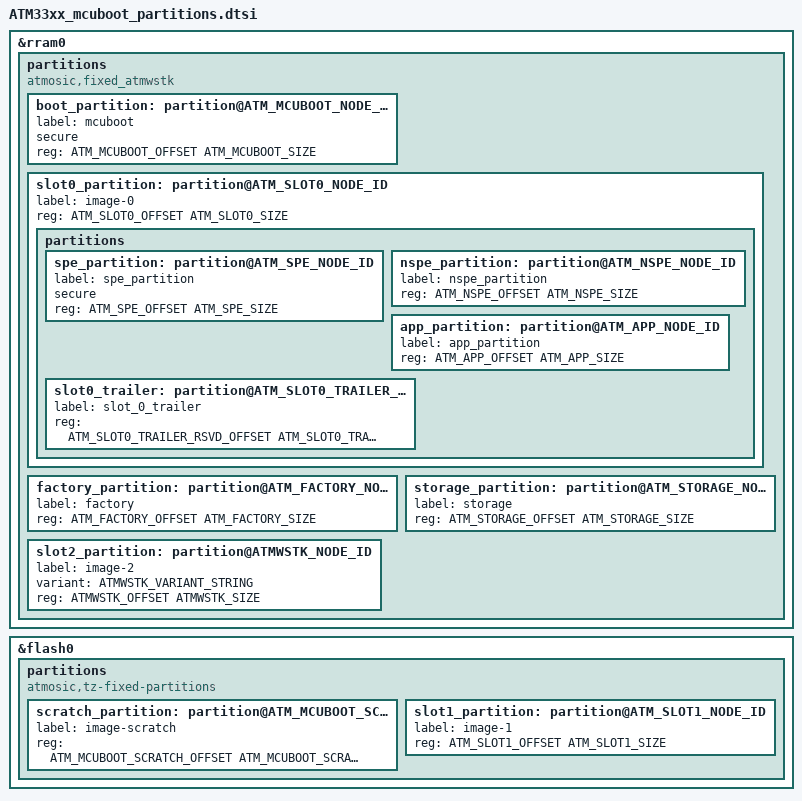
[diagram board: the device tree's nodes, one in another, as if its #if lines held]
/*
 * Copyright (c) 2022-2025 Atmosic
 *
 * SPDX-License-Identifier: Apache-2.0
 */

#if ATM_SPE_SIZE
/delete-node/ &spe_partition;
/delete-node/ &nspe_partition;
#endif
#if ATM_APP_SIZE
/delete-node/ &app_partition;
#endif
/delete-node/ &storage_partition;

#include <arm/atmosic/ATM33xx_mcuboot_partition_defs.h>

&rram0 {
	partitions {
#if ATM_SPE_SIZE
		compatible = "atmosic,fixed_atmwstk", "atmosic,tz-fixed-partitions", "fixed-partitions";
#else
		compatible = "atmosic,fixed_atmwstk", "fixed-partitions";
#endif
		#address-cells = <1>;
		#size-cells = <1>;

		boot_partition: partition@ATM_MCUBOOT_NODE_ID {
			label = "mcuboot";
#if ATM_SPE_SIZE
			secure;
#endif
			reg = <ATM_MCUBOOT_OFFSET ATM_MCUBOOT_SIZE>;
		};
		slot0_partition: partition@ATM_SLOT0_NODE_ID {
			label = "image-0";
			reg = <ATM_SLOT0_OFFSET ATM_SLOT0_SIZE>;
			partitions {
				#address-cells = <1>;
				#size-cells = <1>;
#if ATM_SPE_SIZE
				spe_partition: partition@ATM_SPE_NODE_ID {
					label = "spe_partition";
					secure;
					reg = <ATM_SPE_OFFSET ATM_SPE_SIZE>;
				};
				nspe_partition: partition@ATM_NSPE_NODE_ID {
					label = "nspe_partition";
					reg = <ATM_NSPE_OFFSET ATM_NSPE_SIZE>;
				};
#endif
#if ATM_APP_SIZE
				app_partition: partition@ATM_APP_NODE_ID {
					label = "app_partition";
					reg = <ATM_APP_OFFSET ATM_APP_SIZE>;
				};
#endif
#if ATM_SLOT0_TRAILER_RSVD_SIZE
				slot0_trailer: partition@ATM_SLOT0_TRAILER_NODE_ID {
					label = "slot_0_trailer";
					reg = <ATM_SLOT0_TRAILER_RSVD_OFFSET ATM_SLOT0_TRAILER_RSVD_SIZE>;
				};
#endif
			};
		};
		factory_partition: partition@ATM_FACTORY_NODE_ID {
			label = "factory";
			reg = <ATM_FACTORY_OFFSET ATM_FACTORY_SIZE>;
		};
		storage_partition: partition@ATM_STORAGE_NODE_ID {
			label = "storage";
			reg = <ATM_STORAGE_OFFSET ATM_STORAGE_SIZE>;
		};
#if ATMWSTK_SIZE
		slot2_partition: partition@ATMWSTK_NODE_ID {
			label = "image-2";
			variant = ATMWSTK_VARIANT_STRING;
			reg = <ATMWSTK_OFFSET ATMWSTK_SIZE>;
		};
#endif
	};
};

&flash0 {
	partitions {
		compatible = "atmosic,tz-fixed-partitions", "fixed-partitions";
		#address-cells = <1>;
		#size-cells = <1>;
#if ATM_MCUBOOT_SCRATCH_SIZE
		scratch_partition: partition@ATM_MCUBOOT_SCRATCH_NODE_ID {
			label = "image-scratch";
			reg = <ATM_MCUBOOT_SCRATCH_OFFSET ATM_MCUBOOT_SCRATCH_SIZE>;
		};
#endif
		// slot1 OTA staging area in flash, size must equal slot0_partition
		slot1_partition: partition@ATM_SLOT1_NODE_ID {
			label = "image-1";
			reg = <ATM_SLOT1_OFFSET ATM_SLOT1_SIZE>;
		};
	};
};
